# MM32P0xx register map
Vendor: MindMotion Ltd.; Series: MM32P0; File version: 1.4
CPU: CM0 r0p0, little endian, no MPU, no FPU, 3 interrupt priority bits
Registers are 32-bit, read-write, reset 0x0 unless marked. A register's access mark holds for its fields unless they carry their own. Offsets are from the block's base; [hi:lo] are bit positions; {n}, {i} and the like mark numbered series.

## WWDG — Window watchdog
Base 0x40002C00
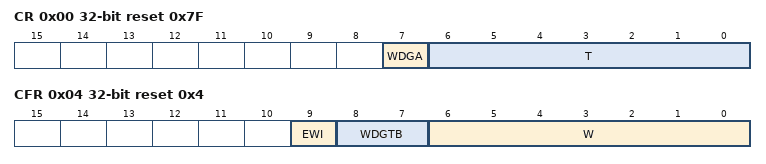
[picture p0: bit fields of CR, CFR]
0x00 CR reset 0x7F
  [7] WDGA — Activation bit
  [6:0] T — 7-bit counter
0x04 CFR reset 0x4
  [9] EWI — Early wakeup interrupt
  [8:7] WDGTB — Timer base
  [6:0] W — 7-bit window value
0x08 SR
  [0] EWIF — Early wakeup interrupt flag

## IWDG — Independent watchdog
Base 0x40003000
0x00 KR wo
  [15:0] KEY — Key value
0x04 PR
  [2:0] PR — Prescaler divider
0x08 RLR
  [11:0] RL — Watchdog counter reload value
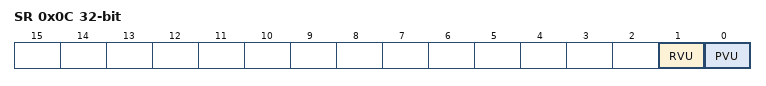
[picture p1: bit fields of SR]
0x0C SR ro
  [1] RVU — Watchdog counter reload value update
  [0] PVU — Watchdog prescaler value update

## PWR — Power control
Base 0x40007000
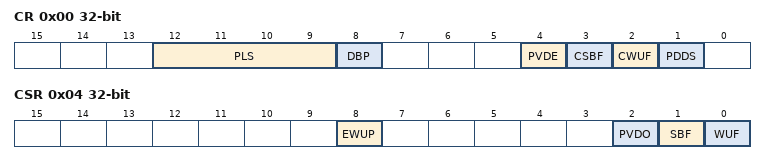
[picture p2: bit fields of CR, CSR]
0x00 CR
  [12:9] PLS — PVD level selection
  [8] DBP — domain write protection
  [4] PVDE — Power voltage detector enable
  [3] CSBF — Clear standby flag
  [2] CWUF — Clear wakeup flag
  [1] PDDS — Power down deepsleep
0x04 CSR
  [8] EWUP — Enable WKUP pin
  [2] PVDO — PVD output
  [1] SBF — Standby flag
  [0] WUF — Wakeup flag

## GPIOA — General purpose I/O
Base 0x48000000
Same registers: GPIOB 0x48000400, GPIOC 0x48000800, GPIOD 0x48000C00
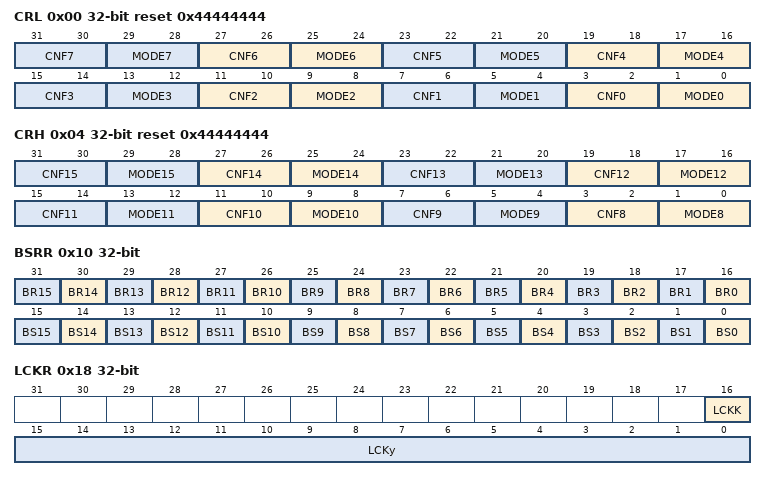
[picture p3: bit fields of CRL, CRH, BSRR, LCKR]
0x00 CRL reset 0x44444444
  [4n+3:4n+2] CNF{n} (n=0..7) — Port {n} configuration bits
  [4n+1:4n] MODE{n} (n=0..7) — Port {n} mode bits
0x04 CRH reset 0x44444444
  [4n-29:4n-30] CNF{n} (n=8..15) — Port {n} configuration bits
  [4n-31:4n-32] MODE{n} (n=8..15) — Port {n} mode bits
0x08 IDR ro
  [15:0] IDRy — Port input data
0x0C ODR
  [15:0] ODRy — Port output data
0x10 BSRR wo
  [n+16] BR{n} (n=0..15) — Port A Reset bit {n}
  [n] BS{n} (n=0..15) — Port A Set bit {n}
0x14 BRR wo
  [15:0] BRy — Port A Reset bit y
0x18 LCKR
  [16] LCKK — Lock key
  [15:0] LCKy — Port A Lock bit y
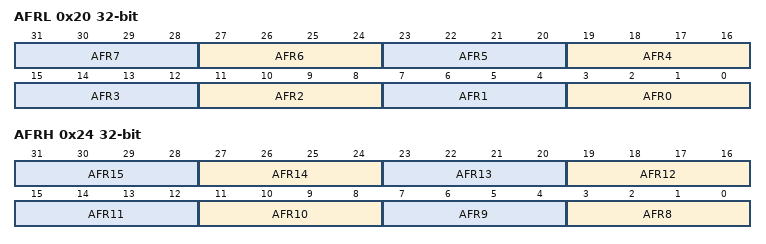
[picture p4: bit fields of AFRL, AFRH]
0x20 AFRL
  [4n+3:4n] AFR{n} (n=0..7)
0x24 AFRH
  [4n-29:4n-32] AFR{n} (n=8..15)

## UART1 — Universal asynchronous receiver transmitter
Base 0x40013800
0x00 TDR
  [7:0] TXREG — Transmit data register
0x04 RDR ro
  [7:0] RXREG — Receive data register
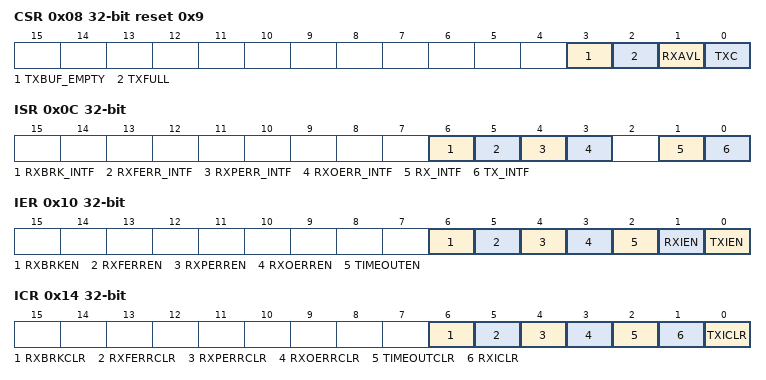
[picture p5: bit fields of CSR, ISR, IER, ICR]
0x08 CSR ro reset 0x9
  [3] TXBUF_EMPTY — Transmit buffer enpty flag bit
  [2] TXFULL — Transmit buffer full flag bit
  [1] RXAVL — Receive valid data flag bit
  [0] TXC — Transmit complete flag bit
0x0C ISR ro
  [6] RXBRK_INTF — Receive frame break interrupt flag bit
  [5] RXFERR_INTF — Frame error interrupt flag bit
  [4] RXPERR_INTF — Parity error interrupt flag bit
  [3] RXOERR_INTF — Receive overflow error interrupt flag bit
  [1] RX_INTF — Receive valid data interrupt flag bit
  [0] TX_INTF — Transmit buffer enpty interrupt flag bit
0x10 IER
  [6] RXBRKEN — Receive frame break interrupt enable bit
  [5] RXFERREN — Frame error interrupt enable bit
  [4] RXPERREN — Parity error interrupt enable bit
  [3] RXOERREN — Receive overflow error interrupt enable bit
  [2] TIMEOUTEN — Receive timeout interrupt enable bit
  [1] RXIEN — Receive buffer interrupt enable bit
  [0] TXIEN — Transmit buffer enpty interrupt enable bit
0x14 ICR wo
  [6] RXBRKCLR — Receive frame break interrupt clear bit
  [5] RXFERRCLR — Frame error interrupt clear bit
  [4] RXPERRCLR — Parity error interrupt clear bit
  [3] RXOERRCLR — Receive overflow error interrupt clear bit
  [2] TIMEOUTCLR — Receive timeout interrupt clear bit
  [1] RXICLR — Receive interrupt clear bit
  [0] TXICLR — Transmit buffer empty interrupt clear bit
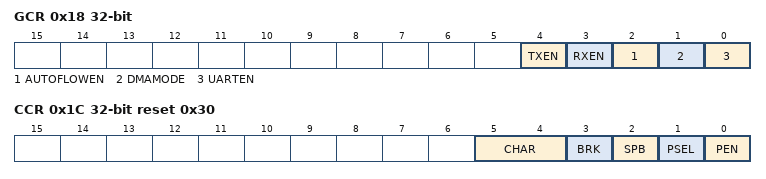
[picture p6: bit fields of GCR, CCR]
0x18 GCR
  [4] TXEN — Enable transmit
  [3] RXEN — Enable receive
  [2] AUTOFLOWEN — Automatic flow control enable bit
  [1] DMAMODE — DMA mode selection bit
  [0] UARTEN — UART mode selection bit
0x1C CCR reset 0x30
  [5:4] CHAR — UART width bit
  [3] BRK — UART transmit frame break
  [2] SPB — Stop bit selection
  [1] PSEL — Parity selection bit
  [0] PEN — Parity enable bit
0x20 BRR reset 0x1
  [15:0] SPBRG — UART baud rate control register
